# MSP432P411V register map
Vendor: Texas Instruments; File version: 3.230
CPU: 
Registers are 32-bit, read-write, reset 0x0 unless marked. A register's access mark holds for its fields unless they carry their own. Offsets are from the block's base; [hi:lo] are bit positions; {n}, {i} and the like mark numbered series.

## ITM
Base 0xE0000000
{0x0+4i} ITM_STIM{i} reset not defined (i=0..31) — ITM Stimulus Port {i}
0xE00 ITM_TER — ITM Trace Enable Register
  [31:0] STIMENA — Bit mask to enable tracing on ITM stimulus ports. One bit per stimulus port.
0xE40 ITM_TPR — ITM Trace Privilege Register
  [3:0] PRIVMASK — Bit mask to enable tracing on ITM stimulus ports: bit [0] = stimulus ports [7:0], bit [1] = stimulus ports [15:8], bit [2] = stimulus ports [23:16], bit [3] = stimulus ports [31:24].
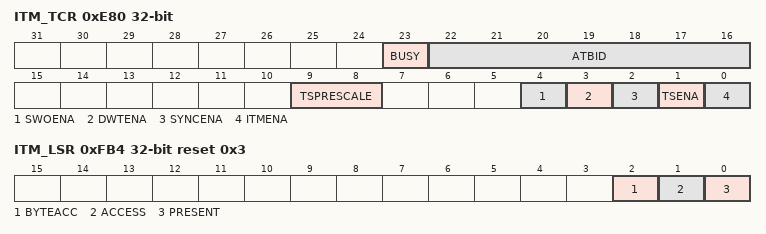
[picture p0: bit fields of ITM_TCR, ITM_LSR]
0xE80 ITM_TCR — ITM Trace Control Register
  [23] BUSY — Set when ITM events present and being drained.
  [22:16] ATBID — ATB ID for CoreSight system.
  [9:8] TSPRESCALE — TSPrescale Timestamp prescaler.
    0=en_0b00 (no prescaling); 1=en_0b01 (divide by 4); 2=en_0b10 (divide by 16); 3=en_0b11 (divide by 64)
  [4] SWOENA — Enables asynchronous clocking of the timestamp counter.
  [3] DWTENA — Enables the DWT stimulus.
  [2] SYNCENA — Enables sync packets for TPIU.
  [1] TSENA — Enables differential timestamps. Differential timestamps are emitted when a packet is written to the FIFO with a non-zero timestamp counter, and when the timestamp counter overflows. Timestamps are emitted during idle times after a fixed number of two million cycles. This provides a time reference for packets and inter-packet gaps. If SWOENA (bit [4]) is set, timestamps are triggered by activity on the internal trace bus only. In this case there is no regular timestamp output when the ITM is idle.
  [0] ITMENA — Enable ITM. This is the master enable, and must be set before ITM Stimulus and Trace Enable registers can be written.
0xEF8 ITM_IWR wo — ITM Integration Write Register
  [0] ATVALIDM — When the integration mode is set: 0 = ATVALIDM clear. 1 = ATVALIDM set.
    0=en_0b0 (ATVALIDM clear); 1=en_0b1 (ATVALIDM set)
0xF00 ITM_IMCR — ITM Integration Mode Control Register
  [0] INTEGRATION
    0=en_0b0 (ATVALIDM normal); 1=en_0b1 (ATVALIDM driven from Integration Write Register)
0xFB0 ITM_LAR wo — ITM Lock Access Register
  [31:0] LOCK_ACCESS — A privileged write of 0xC5ACCE55 enables more write access to Control Register 0xE00::0xFFC. An invalid write removes write access.
0xFB4 ITM_LSR ro reset 0x3 — ITM Lock Status Register
  [2] BYTEACC — You cannot implement 8-bit lock accesses.
  [1] ACCESS — Write access to component is blocked. All writes are ignored, reads are permitted.
  [0] PRESENT — Indicates that a lock mechanism exists for this component.

## FPB
Base 0xE0002000
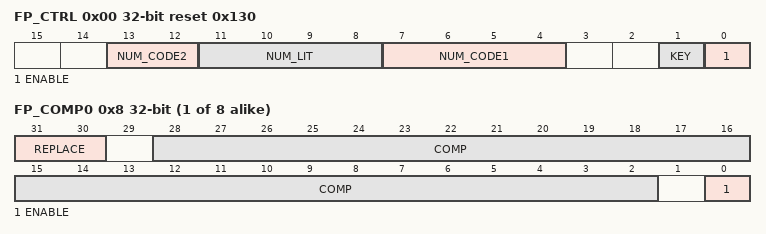
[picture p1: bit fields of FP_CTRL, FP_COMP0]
0x00 FP_CTRL reset 0x130 — Flash Patch Control Register
  [13:12] NUM_CODE2 ro — Number of full banks of code comparators, sixteen comparators per bank. Where less than sixteen code comparators are provided, the bank count is zero, and the number present indicated by NUM_CODE. This read only field contains 3'b000 to indicate 0 banks for Cortex-M4 processor.
  [11:8] NUM_LIT ro — Number of literal slots field.
    0=en_0b0000 (no literal slots); 2=en_0b0010 (two literal slots)
  [7:4] NUM_CODE1 ro — Number of code slots field.
    0=en_0b0000 (no code slots); 2=en_0b0010 (two code slots); 6=en_0b0110 (six code slots)
  [1] KEY wo — Key field. To write to the Flash Patch Control Register, you must write a 1 to this write-only bit.
  [0] ENABLE — Flash patch unit enable bit
    0=en_0b0 (flash patch unit disabled); 1=en_0b1 (flash patch unit enabled)
0x04 FP_REMAP reset not defined — Flash Patch Remap Register
  [28:5] REMAP — Remap base address field.
{0x8+4i} FP_COMP{i} (reset mask 0x1) (i=0..7) — Flash Patch Comparator Registers
  [31:30] REPLACE — This selects what happens when the COMP address is matched. Settings other than b00 are only valid for instruction comparators. Literal comparators ignore non-b00 settings. Address remapping only takes place for the b00 setting.
    0=en_0b00 (remap to remap address. See FP_REMAP); 1=en_0b01 (set BKPT on lower halfword, upper is unaffected); 2=en_0b10 (set BKPT on upper halfword, lower is unaffected); 3=en_0b11 (set BKPT on both lower and upper halfwords.)
  [28:2] COMP — Comparison address.
  [0] ENABLE — Compare and remap enable for Flash Patch Comparator Register {i}. The ENABLE bit of FP_CTRL must also be set to enable comparisons. Reset clears the ENABLE bit.
    0=en_0b0 (Flash Patch Comparator Register {i} compare and remap disabled); 1=en_0b1 (Flash Patch Comparator Register {i} compare and remap enabled)

## RSTCTL
Base 0xE0042000
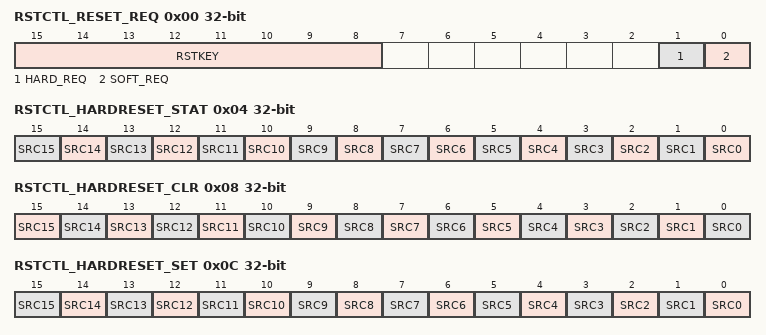
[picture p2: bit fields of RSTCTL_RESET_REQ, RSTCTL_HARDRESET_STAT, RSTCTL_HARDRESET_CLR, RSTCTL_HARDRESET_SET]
0x00 RSTCTL_RESET_REQ (reset mask 0xFFFF00FC) — Reset Request Register
  [15:8] RSTKEY wo — Write key to unlock reset request bits
  [1] HARD_REQ wo — Hard Reset request
  [0] SOFT_REQ wo — Soft Reset request
0x04 RSTCTL_HARDRESET_STAT ro — Hard Reset Status Register
  [n] SRC{n} (n=0..15) — Indicates that SRC{n} was the source of the Hard Reset
0x08 RSTCTL_HARDRESET_CLR (reset mask 0xFFFF0000) — Hard Reset Status Clear Register
  [15] SRC15 wo — Write 1 clears the corresponding bit in the RSTCTL_HRDRESETSTAT_REG
  [n] SRC{n} wo (n=0..14) — Write 1 clears the corresponding bit in the RSTCTL_HARDRESET_STAT
0x0C RSTCTL_HARDRESET_SET — Hard Reset Status Set Register
  [n] SRC{n} wo (n=0..15) — Write 1 sets the corresponding bit in the RSTCTL_HARDRESET_STAT (and initiates a Hard Reset)
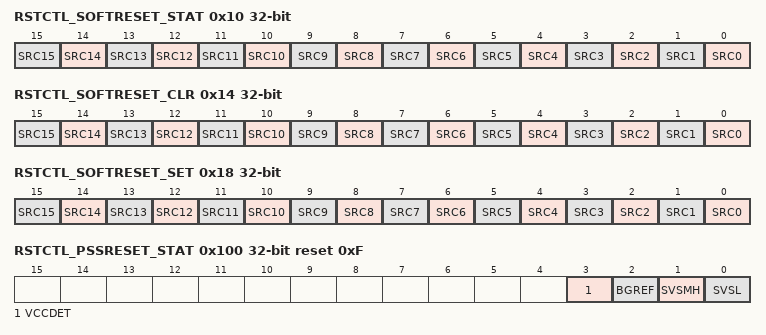
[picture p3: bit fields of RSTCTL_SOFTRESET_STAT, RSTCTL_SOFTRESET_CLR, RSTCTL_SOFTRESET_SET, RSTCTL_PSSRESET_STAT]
0x10 RSTCTL_SOFTRESET_STAT ro — Soft Reset Status Register
  [n] SRC{n} (n=0..15) — If 1, indicates that SRC{n} was the source of the Soft Reset
0x14 RSTCTL_SOFTRESET_CLR — Soft Reset Status Clear Register
  [n] SRC{n} wo (n=0..15) — Write 1 clears the corresponding bit in the RSTCTL_SOFTRESET_STAT
0x18 RSTCTL_SOFTRESET_SET — Soft Reset Status Set Register
  [n] SRC{n} wo (n=0..15) — Write 1 sets the corresponding bit in the RSTCTL_SOFTRESET_STAT (and initiates a Soft Reset)
0x100 RSTCTL_PSSRESET_STAT ro reset 0xF — PSS Reset Status Register
  [3] VCCDET — Indicates if POR was caused by a VCCDET trip condition in the PSS
  [2] BGREF — Indicates if POR was caused by a BGREF not okay condition in the PSS
  [1] SVSMH — Indicates if POR was caused by an SVSMH trip condition int the PSS
  [0] SVSL — Indicates if POR was caused by an SVSL trip condition in the PSS
0x104 RSTCTL_PSSRESET_CLR — PSS Reset Status Clear Register
  [0] CLR wo — Write 1 clears all PSS Reset Flags in the RSTCTL_PSSRESET_STAT
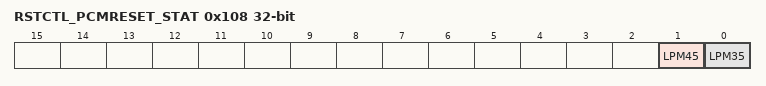
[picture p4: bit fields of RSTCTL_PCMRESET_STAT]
0x108 RSTCTL_PCMRESET_STAT ro — PCM Reset Status Register
  [1] LPM45 — Indicates if POR was caused by PCM due to an exit from LPM4.5
  [0] LPM35 — Indicates if POR was caused by PCM due to an exit from LPM3.5
0x10C RSTCTL_PCMRESET_CLR — PCM Reset Status Clear Register
  [0] CLR wo — Write 1 clears all PCM Reset Flags in the RSTCTL_PCMRESET_STAT
0x110 RSTCTL_PINRESET_STAT ro — Pin Reset Status Register
  [0] RSTNMI — POR was caused by RSTn/NMI pin based reset event
0x114 RSTCTL_PINRESET_CLR — Pin Reset Status Clear Register
  [0] CLR wo — Write 1 clears the RSTn/NMI Pin Reset Flag in RSTCTL_PINRESET_STAT
0x118 RSTCTL_REBOOTRESET_STAT ro — Reboot Reset Status Register
  [0] REBOOT — Indicates if Reboot reset was caused by the SYSCTL module.
0x11C RSTCTL_REBOOTRESET_CLR — Reboot Reset Status Clear Register
  [0] CLR wo — Write 1 clears the Reboot Reset Flag in RSTCTL_REBOOTRESET_STAT
0x120 RSTCTL_CSRESET_STAT ro — CS Reset Status Register
  [0] DCOR_SHT — Indicates if POR was caused by DCO short circuit fault in the external resistor mode
0x124 RSTCTL_CSRESET_CLR — CS Reset Status Clear Register
  [0] CLR wo — Write 1 clears the DCOR_SHT Flag in RSTCTL_CSRESET_STAT as well as DCOR_SHTIFG flag in CSIFG register of clock system
